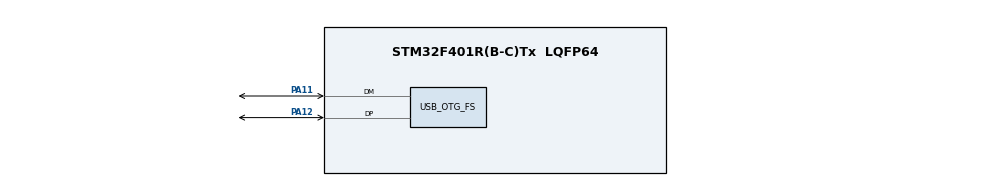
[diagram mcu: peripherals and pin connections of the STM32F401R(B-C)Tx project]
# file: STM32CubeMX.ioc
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Mcu.Family=STM32F4
Mcu.Name=STM32F401R(B-C)Tx
Mcu.Package=LQFP64
NVIC.OTG_FS_IRQn=true\:0\:0\:false\:false\:true\:true\:true\:true
NVIC.PriorityGroup=NVIC_PRIORITYGROUP_4
NVIC.TIM1_BRK_TIM9_IRQn=true\:15\:0\:false\:false\:true\:false\:true\:true
NVIC.TimeBase=TIM1_BRK_TIM9_IRQn
NVIC.TimeBaseIP=TIM9
PA11.Mode=Device_Only
PA11.Signal=USB_OTG_FS_DM
PA12.Mode=Device_Only
PA12.Signal=USB_OTG_FS_DP
PA13.Mode=Serial_Wire
PA13.Signal=SYS_JTMS-SWDIO
PA14.Mode=Serial_Wire
PA14.Signal=SYS_JTCK-SWCLK
PH0\ -\ OSC_IN.Mode=HSE-External-Oscillator
PH0\ -\ OSC_IN.Signal=RCC_OSC_IN
PH1\ -\ OSC_OUT.Mode=HSE-External-Oscillator
PH1\ -\ OSC_OUT.Signal=RCC_OSC_OUT
ProjectManager.HeapSize=0x000
ProjectManager.StackSize=0x800
ProjectManager.TargetToolchain=MDK-ARM V5.32
RCC.48MHZClocksFreq_Value=48000000
RCC.AHBFreq_Value=84000000
RCC.APB1CLKDivider=RCC_HCLK_DIV2
RCC.APB1Freq_Value=42000000
RCC.APB1TimFreq_Value=84000000
RCC.APB2Freq_Value=84000000
RCC.APB2TimFreq_Value=84000000
RCC.CortexFreq_Value=84000000
RCC.HCLKFreq_Value=84000000
RCC.HSE_VALUE=25000000
RCC.HSI_VALUE=16000000
RCC.LSE_VALUE=32768
RCC.PLLM=25
RCC.PLLN=336
RCC.PLLP=RCC_PLLP_DIV4
RCC.PLLQ=7
RCC.SYSCLKFreq_VALUE=84000000
RCC.SYSCLKSource=RCC_SYSCLKSOURCE_PLLCLK
RCC.VCOOutputFreq_Value=336000000
USB_OTG_FS.VirtualMode=Device_Only
VP_SYS_VS_tim9.Mode=TIM9
board=custom

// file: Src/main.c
/* USER CODE BEGIN Header */
/**
  ******************************************************************************
  * @file           : main.c
  * @brief          : Main program body
  ******************************************************************************
  * @attention
  *
  * Copyright (c) 2026 STMicroelectronics.
  * All rights reserved.
  *
  * This software is licensed under terms that can be found in the LICENSE file
  * in the root directory of this software component.
  * If no LICENSE file comes with this software, it is provided AS-IS.
  *
  ******************************************************************************
  */
/* USER CODE END Header */
#include "main.h"
#include "usb_otg.h"
#include "gpio.h"

/* USER CODE BEGIN Includes */

#include "app_main.h"
/* USER CODE END Includes */

void SystemClock_Config(void);

int main(void)
{

  /* MCU Configuration--------------------------------------------------------*/

  /* Reset of all peripherals, Initializes the Flash interface and the Systick. */
  HAL_Init();

  /* Configure the system clock */
  SystemClock_Config();

  /* Initialize all configured peripherals */
  MX_GPIO_Init();
  MX_USB_OTG_FS_PCD_Init();
  /* USER CODE BEGIN 2 */

  //to APP_MAIN_C
  app_main();

  /* USER CODE END 2 */

  /* Infinite loop */
  while (1)
  {

  }
}

void SystemClock_Config(void)
{
  LL_FLASH_SetLatency(LL_FLASH_LATENCY_2);
  while(LL_FLASH_GetLatency()!= LL_FLASH_LATENCY_2)
  {
  }
  LL_PWR_SetRegulVoltageScaling(LL_PWR_REGU_VOLTAGE_SCALE2);
  LL_RCC_HSE_Enable();

   /* Wait till HSE is ready */
  while(LL_RCC_HSE_IsReady() != 1)
  {

  }
  LL_RCC_PLL_ConfigDomain_SYS(LL_RCC_PLLSOURCE_HSE, LL_RCC_PLLM_DIV_25, 336, LL_RCC_PLLP_DIV_4);
  LL_RCC_PLL_ConfigDomain_48M(LL_RCC_PLLSOURCE_HSE, LL_RCC_PLLM_DIV_25, 336, LL_RCC_PLLQ_DIV_7);
  LL_RCC_PLL_Enable();

   /* Wait till PLL is ready */
  while(LL_RCC_PLL_IsReady() != 1)
  {

  }
  while (LL_PWR_IsActiveFlag_VOS() == 0)
  {
  }
  LL_RCC_SetAHBPrescaler(LL_RCC_SYSCLK_DIV_1);
  LL_RCC_SetAPB1Prescaler(LL_RCC_APB1_DIV_2);
  LL_RCC_SetAPB2Prescaler(LL_RCC_APB2_DIV_1);
  LL_RCC_SetSysClkSource(LL_RCC_SYS_CLKSOURCE_PLL);

   /* Wait till System clock is ready */
  while(LL_RCC_GetSysClkSource() != LL_RCC_SYS_CLKSOURCE_STATUS_PLL)
  {

  }
  LL_SetSystemCoreClock(84000000);

   /* Update the time base */
  if (HAL_InitTick (TICK_INT_PRIORITY) != HAL_OK)
  {
    Error_Handler();
  }
  LL_RCC_SetTIMPrescaler(LL_RCC_TIM_PRESCALER_TWICE);
}

void HAL_TIM_PeriodElapsedCallback(TIM_HandleTypeDef *htim)
{
  if (htim->Instance == TIM9)
  {
    HAL_IncTick();
  }
}

void Error_Handler(void)
{
  __disable_irq();
  while (1)
  {
  }
}
